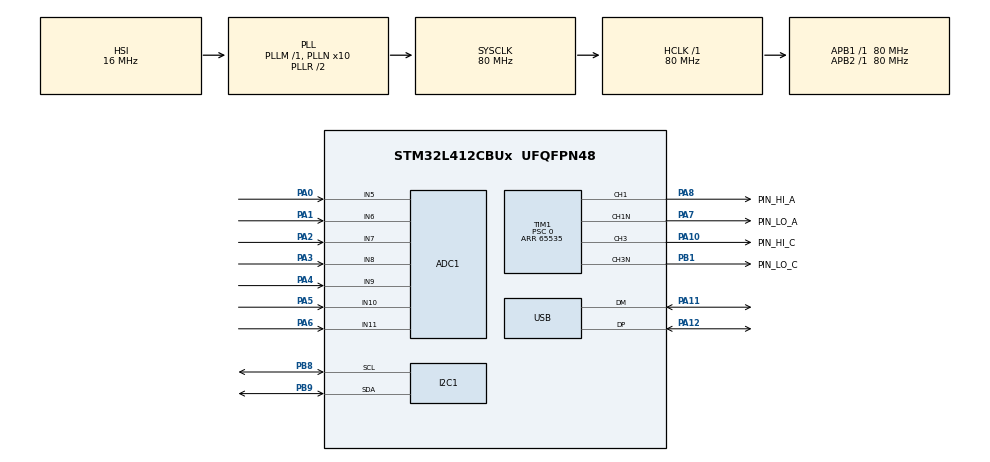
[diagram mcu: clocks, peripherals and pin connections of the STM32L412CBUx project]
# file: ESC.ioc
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ADC1.Channel-1\#ChannelRegularConversion=ADC_CHANNEL_5
ADC1.Channel-10\#ChannelRegularConversion=ADC_CHANNEL_8
ADC1.Channel-11\#ChannelRegularConversion=ADC_CHANNEL_9
ADC1.Channel-12\#ChannelRegularConversion=ADC_CHANNEL_10
ADC1.Channel-13\#ChannelRegularConversion=ADC_CHANNEL_11
ADC1.Channel-8\#ChannelRegularConversion=ADC_CHANNEL_6
ADC1.Channel-9\#ChannelRegularConversion=ADC_CHANNEL_7
ADC1.NbrOfConversion=7
ADC1.NbrOfConversionFlag=1
ADC1.OffsetNumber-1\#ChannelRegularConversion=ADC_OFFSET_NONE
ADC1.OffsetNumber-10\#ChannelRegularConversion=ADC_OFFSET_NONE
ADC1.OffsetNumber-11\#ChannelRegularConversion=ADC_OFFSET_NONE
ADC1.OffsetNumber-12\#ChannelRegularConversion=ADC_OFFSET_NONE
ADC1.OffsetNumber-13\#ChannelRegularConversion=ADC_OFFSET_NONE
ADC1.OffsetNumber-8\#ChannelRegularConversion=ADC_OFFSET_NONE
ADC1.OffsetNumber-9\#ChannelRegularConversion=ADC_OFFSET_NONE
ADC1.Rank-1\#ChannelRegularConversion=1
ADC1.Rank-10\#ChannelRegularConversion=4
ADC1.Rank-11\#ChannelRegularConversion=5
ADC1.Rank-12\#ChannelRegularConversion=6
ADC1.Rank-13\#ChannelRegularConversion=7
ADC1.Rank-8\#ChannelRegularConversion=2
ADC1.Rank-9\#ChannelRegularConversion=3
ADC1.SamplingTime-1\#ChannelRegularConversion=ADC_SAMPLETIME_24CYCLES_5
ADC1.SamplingTime-10\#ChannelRegularConversion=ADC_SAMPLETIME_2CYCLES_5
ADC1.SamplingTime-11\#ChannelRegularConversion=ADC_SAMPLETIME_2CYCLES_5
ADC1.SamplingTime-12\#ChannelRegularConversion=ADC_SAMPLETIME_2CYCLES_5
ADC1.SamplingTime-13\#ChannelRegularConversion=ADC_SAMPLETIME_2CYCLES_5
ADC1.SamplingTime-8\#ChannelRegularConversion=ADC_SAMPLETIME_2CYCLES_5
ADC1.SamplingTime-9\#ChannelRegularConversion=ADC_SAMPLETIME_2CYCLES_5
ADC1.master=1
I2C1.Timing=0x10D19CE4
Mcu.Family=STM32L4
Mcu.Name=STM32L412CBUx
Mcu.Package=UFQFPN48
NVIC.PriorityGroup=NVIC_PRIORITYGROUP_4
NVIC.USB_IRQn=true\:0\:0\:false\:false\:true\:false\:true\:true
PA0.GPIO_Mode=GPIO_MODE_ANALOG_ADC_CONTROL
PA0.GPIO_PuPd=GPIO_NOPULL
PA0.Signal=ADCx_IN5
PA1.GPIO_Mode=GPIO_MODE_ANALOG_ADC_CONTROL
PA1.GPIO_PuPd=GPIO_NOPULL
PA1.Signal=ADCx_IN6
PA10.GPIO_Label=PIN_HI_C
PA10.Signal=S_TIM1_CH3
PA11.Mode=Device
PA11.Signal=USB_DM
PA12.Mode=Device
PA12.Signal=USB_DP
PA13\ (JTMS/SWDIO).Mode=Serial_Wire
PA13\ (JTMS/SWDIO).Signal=SYS_JTMS-SWDIO
PA14\ (JTCK/SWCLK).Mode=Serial_Wire
PA14\ (JTCK/SWCLK).Signal=SYS_JTCK-SWCLK
PA2.GPIO_Mode=GPIO_MODE_ANALOG_ADC_CONTROL
PA2.GPIO_PuPd=GPIO_NOPULL
PA2.Signal=ADCx_IN7
PA3.GPIO_Mode=GPIO_MODE_ANALOG_ADC_CONTROL
PA3.GPIO_PuPd=GPIO_NOPULL
PA3.Signal=ADCx_IN8
PA4.GPIO_Mode=GPIO_MODE_ANALOG_ADC_CONTROL
PA4.GPIO_PuPd=GPIO_NOPULL
PA4.Signal=ADCx_IN9
PA5.GPIO_Mode=GPIO_MODE_ANALOG_ADC_CONTROL
PA5.GPIO_PuPd=GPIO_NOPULL
PA5.Signal=ADCx_IN10
PA6.GPIO_Mode=GPIO_MODE_ANALOG_ADC_CONTROL
PA6.GPIO_PuPd=GPIO_NOPULL
PA6.Signal=ADCx_IN11
PA7.GPIO_Label=PIN_LO_A
PA7.Mode=PWM Generation1 CH1 CH1N
PA7.Signal=TIM1_CH1N
PA8.GPIO_Label=PIN_HI_A
PA8.Signal=S_TIM1_CH1
PB1.GPIO_Label=PIN_LO_C
PB1.Mode=PWM Generation3 CH3 CH3N
PB1.Signal=TIM1_CH3N
PB8.Mode=I2C
PB8.Signal=I2C1_SCL
PB9.Mode=I2C
PB9.Signal=I2C1_SDA
PH0-OSC_IN\ (PH0).Mode=HSE-External-Oscillator
PH0-OSC_IN\ (PH0).Signal=RCC_OSC_IN
PH1-OSC_OUT\ (PH1).Mode=HSE-External-Oscillator
PH1-OSC_OUT\ (PH1).Signal=RCC_OSC_OUT
ProjectManager.HeapSize=0x200
ProjectManager.StackSize=0x400
ProjectManager.TargetToolchain=CMake
RCC.ADCFreq_Value=80000000
RCC.AHBFreq_Value=80000000
RCC.APB1Freq_Value=80000000
RCC.APB1TimFreq_Value=80000000
RCC.APB2Freq_Value=80000000
RCC.APB2TimFreq_Value=80000000
RCC.CortexFreq_Value=80000000
RCC.HCLKFreq_Value=80000000
RCC.HSE_VALUE=12000000
RCC.HSI48_VALUE=48000000
RCC.HSI_VALUE=16000000
RCC.LSE_VALUE=32768
RCC.MSIClockRange=RCC_MSIRANGE_11
RCC.MSI_VALUE=48000000
RCC.PLLN=10
RCC.PLLSourceVirtual=RCC_PLLSOURCE_HSI
RCC.SYSCLKFreq_VALUE=80000000
RCC.SYSCLKSource=RCC_SYSCLKSOURCE_PLLCLK
RCC.USBFreq_Value=48000000
RCC.VCOOutputFreq_Value=160000000
SH.ADCx_IN10.0=ADC1_IN10,IN10-Single-Ended
SH.ADCx_IN11.0=ADC1_IN11,IN11-Single-Ended
SH.ADCx_IN11.1=ADC2_IN11
SH.ADCx_IN5.0=ADC1_IN5,IN5-Single-Ended
SH.ADCx_IN6.0=ADC1_IN6,IN6-Single-Ended
SH.ADCx_IN7.0=ADC1_IN7,IN7-Single-Ended
SH.ADCx_IN8.0=ADC1_IN8,IN8-Single-Ended
SH.ADCx_IN9.0=ADC1_IN9,IN9-Single-Ended
SH.S_TIM1_CH1.0=TIM1_CH1,PWM Generation1 CH1 CH1N
SH.S_TIM1_CH3.0=TIM1_CH3,PWM Generation3 CH3 CH3N
TIM1.AutoReloadPreload=TIM_AUTORELOAD_PRELOAD_ENABLE
TIM1.Channel-PWM\ Generation1\ CH1\ CH1N=TIM_CHANNEL_1
TIM1.Channel-PWM\ Generation3\ CH3\ CH3N=TIM_CHANNEL_3
TIM1.ClockDivision=TIM_CLOCKDIVISION_DIV1
TIM1.DeadTime=100
TIM1.OCNPolarity_1=TIM_OCNPOLARITY_HIGH
TIM1.Period=65535
TIM1.Prescaler=0
TIM1.Pulse-PWM\ Generation1\ CH1\ CH1N=0
TIM1.RepetitionCounter=0
USB_DEVICE.CLASS_NAME_FS=CDC
USB_DEVICE.USBD_DEBUG_LEVEL=3
USB_DEVICE.VirtualMode=Cdc
USB_DEVICE.VirtualModeFS=Cdc_FS
VP_TIM1_VS_ClockSourceINT.Mode=Internal
VP_USB_DEVICE_VS_USB_DEVICE_CDC_FS.Mode=CDC_FS
board=custom

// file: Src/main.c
/* USER CODE BEGIN Header */
/**
 ******************************************************************************
 * @file           : main.c
 * @brief          : Main program body
 ******************************************************************************
 * @attention
 *
 * Copyright (c) 2025 STMicroelectronics.
 * All rights reserved.
 *
 * This software is licensed under terms that can be found in the LICENSE file
 * in the root directory of this software component.
 * If no LICENSE file comes with this software, it is provided AS-IS.
 *
 ******************************************************************************
 */
/* USER CODE END Header */
#include "main.h"
#include "adc.h"
#include "i2c.h"
#include "tim.h"
#include "usb_device.h"
#include "gpio.h"

/* USER CODE BEGIN Includes */
#include "debugf_vcp.h"
#include "usbd_cdc.h"
/* USER CODE END Includes */

/* USER CODE BEGIN PTD */
extern ADC_HandleTypeDef hadc1;
// extern uint8_t *vcp_buffer_recieve;
/* USER CODE END PTD */

void SystemClock_Config(void);
/* USER CODE BEGIN PFP */
// float read_ADC_Value(ADC_HandleTypeDef *hadc, uint32_t channel);
/* USER CODE END PFP */

int main(void)
{

  /* MCU Configuration--------------------------------------------------------*/

  /* Reset of all peripherals, Initializes the Flash interface and the Systick. */
  HAL_Init();

  /* Configure the system clock */
  SystemClock_Config();

  /* Initialize all configured peripherals */
  MX_GPIO_Init();
  MX_USB_DEVICE_Init();
  MX_ADC1_Init();
  MX_I2C1_Init();
  MX_TIM1_Init();
  /* USER CODE BEGIN 2 */
  HAL_Delay(1000);
  print_startup();
  /* USER CODE END 2 */

  /* Infinite loop */
  /* USER CODE BEGIN WHILE */
  HAL_TIM_PWM_Start(&htim1, TIM_CHANNEL_1);
  HAL_TIMEx_PWMN_Start(&htim1, TIM_CHANNEL_1); // starts inverted channel
  // HAL_ADC_Start_DMA(&hadc1, adc_buffer, 7);

  while (1)
  {
    console_check();
    HAL_Delay(10);
    // extern ADC_HandleTypeDef hadc1;
    // debugf(">VC:%f\n", read_ADC_Value(&hadc1, ADC_CHANNEL_5) * (1 + 5.1));
    // debugf(">IC:%f\n", read_ADC_Value(&hadc1, ADC_CHANNEL_6));
    // debugf(">VB:%f\n", read_ADC_Value(&hadc1, ADC_CHANNEL_7) * (1 + 5.1));
    // debugf(">IB:%f\n", read_ADC_Value(&hadc1, ADC_CHANNEL_8));
    // debugf(">VA:%f\n", read_ADC_Value(&hadc1, ADC_CHANNEL_9) * (1 + 5.1));
    // debugf(">IA:%f\n", read_ADC_Value(&hadc1, ADC_CHANNEL_10));
    // debugf(">BatDIV:%f\n", read_ADC_Value(&hadc1, ADC_CHANNEL_11) * (1 + 5.1));
    // debugf("\n");

    /* USER CODE END WHILE */

    /* USER CODE BEGIN 3 */
    // HAL_GPIO_TogglePin(PIN_HI_C_GPIO_Port,PIN_HI_C_Pin);
    // HAL_GPIO_TogglePin(PIN_LO_C_GPIO_Port,PIN_LO_C_Pin);
  }
  /* USER CODE END 3 */
}

void SystemClock_Config(void)
{
  RCC_OscInitTypeDef RCC_OscInitStruct = {0};
  RCC_ClkInitTypeDef RCC_ClkInitStruct = {0};

  /** Configure the main internal regulator output voltage
  */
  if (HAL_PWREx_ControlVoltageScaling(PWR_REGULATOR_VOLTAGE_SCALE1) != HAL_OK)
  {
    Error_Handler();
  }

  /** Initializes the RCC Oscillators according to the specified parameters
  * in the RCC_OscInitTypeDef structure.
  */
  RCC_OscInitStruct.OscillatorType = RCC_OSCILLATORTYPE_HSI|RCC_OSCILLATORTYPE_MSI;
  RCC_OscInitStruct.HSIState = RCC_HSI_ON;
  RCC_OscInitStruct.HSICalibrationValue = RCC_HSICALIBRATION_DEFAULT;
  RCC_OscInitStruct.MSIState = RCC_MSI_ON;
  RCC_OscInitStruct.MSICalibrationValue = 0;
  RCC_OscInitStruct.MSIClockRange = RCC_MSIRANGE_11;
  RCC_OscInitStruct.PLL.PLLState = RCC_PLL_ON;
  RCC_OscInitStruct.PLL.PLLSource = RCC_PLLSOURCE_HSI;
  RCC_OscInitStruct.PLL.PLLM = 1;
  RCC_OscInitStruct.PLL.PLLN = 10;
  RCC_OscInitStruct.PLL.PLLQ = RCC_PLLQ_DIV2;
  RCC_OscInitStruct.PLL.PLLR = RCC_PLLR_DIV2;
  if (HAL_RCC_OscConfig(&RCC_OscInitStruct) != HAL_OK)
  {
    Error_Handler();
  }

  /** Initializes the CPU, AHB and APB buses clocks
  */
  RCC_ClkInitStruct.ClockType = RCC_CLOCKTYPE_HCLK|RCC_CLOCKTYPE_SYSCLK
                              |RCC_CLOCKTYPE_PCLK1|RCC_CLOCKTYPE_PCLK2;
  RCC_ClkInitStruct.SYSCLKSource = RCC_SYSCLKSOURCE_PLLCLK;
  RCC_ClkInitStruct.AHBCLKDivider = RCC_SYSCLK_DIV1;
  RCC_ClkInitStruct.APB1CLKDivider = RCC_HCLK_DIV1;
  RCC_ClkInitStruct.APB2CLKDivider = RCC_HCLK_DIV1;

  if (HAL_RCC_ClockConfig(&RCC_ClkInitStruct, FLASH_LATENCY_4) != HAL_OK)
  {
    Error_Handler();
  }
}

void Error_Handler(void)
{
  __disable_irq();
  while (1)
  {
  }
}
